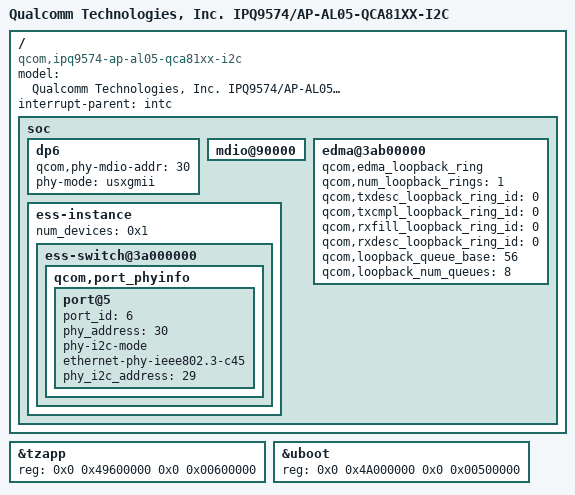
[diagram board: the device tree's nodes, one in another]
// SPDX-License-Identifier: (GPL-2.0+ OR BSD-3-Clause)
/*
 * IPQ9574 AL05-QCA81XX-I2C board device tree source
 *
 * Copyright (c) 2020-2021 The Linux Foundation. All rights reserved.
 * Copyright (c) 2021-2024 Qualcomm Innovation Center, Inc. All rights reserved.
 */

/dts-v1/;

#include "ipq9574-al02-c4.dts"

/ {
	#address-cells = <0x2>;
	#size-cells = <0x2>;
	model = "Qualcomm Technologies, Inc. IPQ9574/AP-AL05-QCA81XX-I2C";
	compatible = "qcom,ipq9574-ap-al05-qca81xx-i2c", "qcom,ipq9574-al05-qca81xx-i2c", "qcom,ipq9574";
	interrupt-parent = <&intc>;

	soc {
		dp6 {
			qcom,phy-mdio-addr = <30>;
			phy-mode = "usxgmii";
		};
		mdio@90000 {
			/delete-node/ethernet-phy@5;
		};

		edma@3ab00000 {
			qcom,edma_loopback_ring;
			qcom,num_loopback_rings = <1>;
			qcom,txdesc_loopback_ring_id = <0>;
			qcom,txcmpl_loopback_ring_id = <0>;
			qcom,rxfill_loopback_ring_id = <0>;
			qcom,rxdesc_loopback_ring_id = <0>;
			qcom,loopback_queue_base = <56>;
			qcom,loopback_num_queues = <8>;
		};

		ess-instance {
			num_devices = <0x1>;
			ess-switch@3a000000 {
				qcom,port_phyinfo {
					port@5 {
						port_id = <6>;
						phy_address = <30>;
						phy-i2c-mode; /*i2c access phy */
						ethernet-phy-ieee802.3-c45;
						phy_i2c_address = <29>;
					};
				};

			};
		};
	};
};

/* Increase the uboot reserved memory region to 5MB, accordingly update the
 * TZApp region as well
 */

&tzapp {
	reg = <0x0 0x49600000 0x0 0x00600000>;
};

&uboot {
	reg = <0x0 0x4A000000 0x0 0x00500000>;
};
